# nrf54lm20a_flpr register map
Vendor: Nordic Semiconductor; Series: nrf54l; File version: 1
Registers are 32-bit, read-write, reset 0x0 unless marked. A register's access mark holds for its fields unless they carry their own. Offsets are from the block's base; [hi:lo] are bit positions; lines under a group give offsets from that group; {n}, {i} and the like mark numbered series; 'fields as' and 'values as' point back to an identical list.

## GLOBAL_FICR_NS — Factory Information Configuration Registers
Base 0x00FFC000
0x300 INFO group — Device info
  0x00 CONFIGID ro reset 0xFFFFFFFF — Configuration identifier
    [15:0] HWID — Identification number for the HW
  {0x4+4j} DEVICEID[{j}] (j=0..1) ro reset 0xFFFFFFFF — Description collection: Device identifier
    [31:0] DEVICEID — 64 bit unique device identifier
  {0xC+4j} UUID[{j}] (j=0..3) ro reset 0xFFFFFFFF — Description collection: 128-bit Universally Unique IDentifier (UUID).
    [31:0] UUID — Device UUID [n].
  0x1C PART ro reset 0xFFFFFFFF — Part code
    [31:0] PART
      0x54BC20A=N54LM20A (nRF54LM20A); 0x54BC20B=N54LM20B (nRF54LM20B); 0xFFFFFFFF=Unspecified
  0x20 VARIANT ro reset 0xFFFFFFFF — Function variant code, Hardware version code, and Production configuration code encoded as ASCII.
    [31:0] VARIANT — Function variant code, Hardware version code, and Production configuration code encoded as ASCII
      0x41414230=AAB0 (Example encoding for AAB0 - Function variant code AA, Hardware version code B, Production configuration code 0); 0xFFFFFFFF=Unspecified
  0x24 PACKAGE ro reset 0xFFFFFFFF — Package option
    [31:0] PACKAGE
      0xFFFFFFFF=Unspecified
  0x28 RAM ro reset 0xFFFFFFFF — RAM size (KB)
    [31:0] RAM
      0x200=K512 (512 kByte RAM); 0xFFFFFFFF=Unspecified
  0x2C RRAM ro reset 0xFFFFFFFF — RRAM size (KB)
    [31:0] RRAM
      0x7F4=K2036 (2036 KByte RRAM); 0xFFFFFFFF=Unspecified
{0x380+4i} ER[{i}] (i=0..3) ro reset 0xFFFFFFFF — Description collection: Common encryption root key, word n
  [31:0] ER — Encryption Root, word n
{0x390+4i} IR[{i}] (i=0..3) ro reset 0xFFFFFFFF — Description collection: Common identity root key, word n
  [31:0] IR — Identity Root, word n
0x3A0 DEVICEADDRTYPE ro reset 0xFFFFFFFF — Device address type
  [0] DEVICEADDRTYPE
    0=Public address; 1=Random address
{0x3A4+4i} DEVICEADDR[{i}] (i=0..1) ro reset 0xFFFFFFFF — Description collection: Device address n
  [31:0] DEVICEADDR — 48 bit device address
{0x400+8i} TRIMCNF[{i}] (i=0..63) group — Unspecified
  0x00 ADDR ro reset 0xFFFFFFFF — Description cluster: Address of the register which will be written
    [31:0] Address
  0x04 DATA ro reset 0xFFFFFFFF — Description cluster: Data to be written into the register
0x600 NFC group — Unspecified
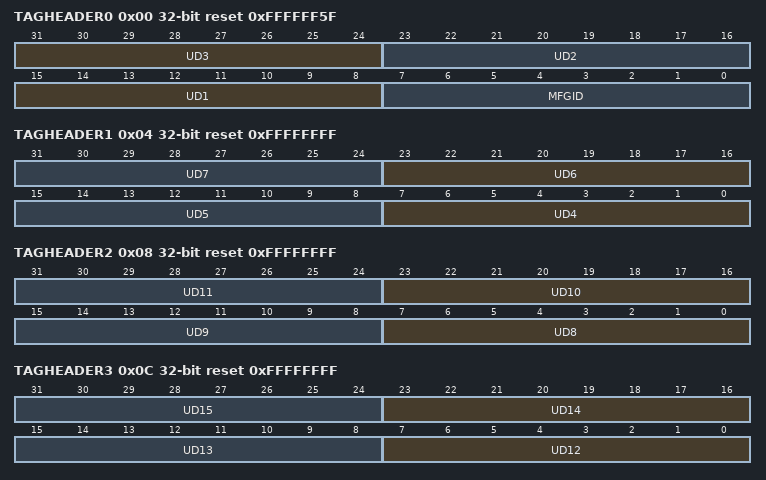
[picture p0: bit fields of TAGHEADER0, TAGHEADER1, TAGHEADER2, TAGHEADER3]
  0x00 TAGHEADER0 ro reset 0xFFFFFF5F — Default header for NFC Tag. Software can read these values to populate NFCID1_3RD_LAST, NFCID1_2ND_LAST and NFCID1_LAST.
    [31:24] UD3 — Unique identifier byte 3
    [23:16] UD2 — Unique identifier byte 2
    [15:8] UD1 — Unique identifier byte 1
    [7:0] MFGID — Default Manufacturer ID: Nordic Semiconductor ASA has ICM 0x5F
  0x04 TAGHEADER1 ro reset 0xFFFFFFFF — Default header for NFC Tag. Software can read these values to populate NFCID1_3RD_LAST, NFCID1_2ND_LAST and NFCID1_LAST.
    [8n-25:8n-32] UD{n} (n=4..7) — Unique identifier byte {n}
  0x08 TAGHEADER2 ro reset 0xFFFFFFFF — Default header for NFC Tag. Software can read these values to populate NFCID1_3RD_LAST, NFCID1_2ND_LAST and NFCID1_LAST.
    [8n-57:8n-64] UD{n} (n=8..11) — Unique identifier byte {n}
  0x0C TAGHEADER3 ro reset 0xFFFFFFFF — Default header for NFC Tag. Software can read these values to populate NFCID1_3RD_LAST, NFCID1_2ND_LAST and NFCID1_LAST.
    [8n-89:8n-96] UD{n} (n=12..15) — Unique identifier byte {n}
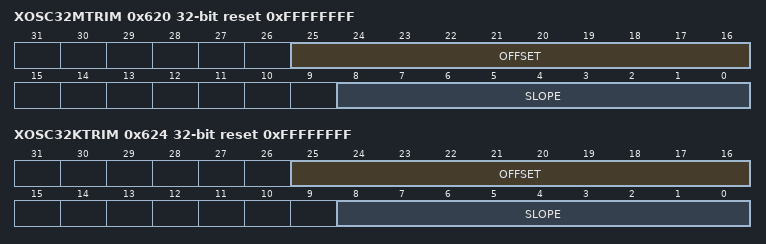
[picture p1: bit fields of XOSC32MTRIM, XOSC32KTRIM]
0x620 XOSC32MTRIM ro reset 0xFFFFFFFF — XOSC32M capacitor selection trim values
  [25:16] OFFSET — Offset trim factor on integer form
  [8:0] SLOPE — Slope trim factor on twos complement form
0x624 XOSC32KTRIM ro reset 0xFFFFFFFF — XOSC32K capacitor selection trim values
  fields as XOSC32MTRIM

## VPRCLIC_NS — VPR CLIC registers
Base 0xF0000000
0x00 CLIC group — Unspecified
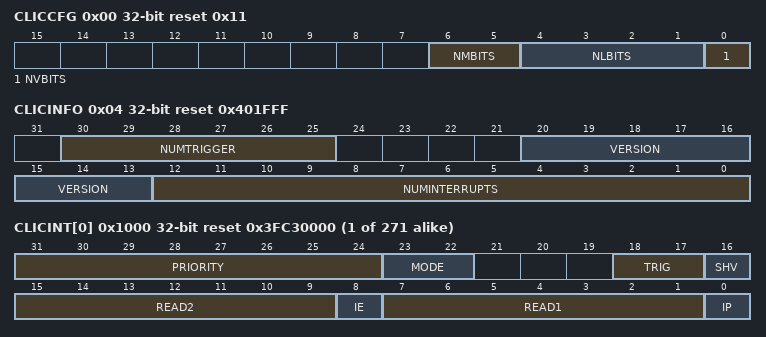
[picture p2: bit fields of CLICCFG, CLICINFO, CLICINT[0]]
  0x00 CLICCFG ro reset 0x11 — CLIC configuration.
    [6:5] NMBITS — Interrupt privilege mode.
      0=ModeM (All interrupts are M-mode only)
    [4:1] NLBITS — Interrupt level encoding.
      8=Eight (8 bits = interrupt levels encoded in eight bits)
    [0] NVBITS — Selective interrupt hardware vectoring.
      1=Implemented (Selective interrupt hardware vectoring is implemented)
  0x04 CLICINFO ro reset 0x401FFF — CLIC information.
    [30:25] NUMTRIGGER — Number of maximum interrupt triggers supported
    [20:13] VERSION
    [12:0] NUMINTERRUPTS — Maximum number of interrupts supported.
  {0x1000+4j} CLICINT[{j}] (j=0..270) reset 0x3FC30000 — Description collection: Interrupt control register for IRQ number [n].
    [31:24] PRIORITY — Interrupt priority level
      63=PRIO3F (Priority level 0x3F); 127=PRIO7F (Priority level 0x7F); 191=PRIOBF (Priority level 0xBF); 255=PRIOFF (Priority level 0xFF); 63=PRIOLEVEL0 (Deprecated enumerator - Priority level 0); 127=PRIOLEVEL1 (Deprecated enumerator - Priority level 1); 191=PRIOLEVEL2 (Deprecated enumerator - Priority level 2); 255=PRIOLEVEL3 (Deprecated enumerator - Priority level 3)
    [23:22] MODE ro — Privilege mode.
      3=MachineMode
    [18:17] TRIG ro — Trigger type and polarity for each interrupt input.
      1=EdgeTriggered (Interrupts are edge-triggered)
    [16] SHV ro — Selective Hardware Vectoring.
      1=Vectored (Hardware vectored)
    [15:9] READ2 ro — Read as 0, write ignored.
    [8] IE — Interrupt enable bit.
      0=Disabled (Interrupt disabled); 1=Enabled (Interrupt enabled)
    [7:1] READ1 ro — Read as 0, write ignored.
    [0] IP — Interrupt Pending bit.
      0=NotPending (Interrupt not pending); 1=Pending (Interrupt pending)

## Notices in the file
Copyright (c) 2010 - 2026, Nordic Semiconductor ASA All rights reserved.
SPDX-License-Identifier: BSD-3-Clause
Redistribution and use in source and binary forms, with or without
modification, are permitted provided that the following conditions are met:
1. Redistributions of source code must retain the above copyright notice, this
list of conditions and the following disclaimer.
2. Redistributions in binary form must reproduce the above copyright
notice, this list of conditions and the following disclaimer in the
documentation and/or other materials provided with the distribution.
3. Neither the name of Nordic Semiconductor ASA nor the names of its
contributors may be used to endorse or promote products derived from this
software without specific prior written permission.
THIS SOFTWARE IS PROVIDED BY THE COPYRIGHT HOLDERS AND CONTRIBUTORS "AS IS"
AND ANY EXPRESS OR IMPLIED WARRANTIES, INCLUDING, BUT NOT LIMITED TO, THE
IMPLIED WARRANTIES OF MERCHANTABILITY, AND FITNESS FOR A PARTICULAR PURPOSE
ARE DISCLAIMED. IN NO EVENT SHALL NORDIC SEMICONDUCTOR ASA OR CONTRIBUTORS BE
LIABLE FOR ANY DIRECT, INDIRECT, INCIDENTAL, SPECIAL, EXEMPLARY, OR
CONSEQUENTIAL DAMAGES (INCLUDING, BUT NOT LIMITED TO, PROCUREMENT OF
SUBSTITUTE GOODS OR SERVICES; LOSS OF USE, DATA, OR PROFITS; OR BUSINESS
INTERRUPTION) HOWEVER CAUSED AND ON ANY THEORY OF LIABILITY, WHETHER IN
CONTRACT, STRICT LIABILITY, OR TORT (INCLUDING NEGLIGENCE OR OTHERWISE)
ARISING IN ANY WAY OUT OF THE USE OF THIS SOFTWARE, EVEN IF ADVISED OF THE
POSSIBILITY OF SUCH DAMAGE.
